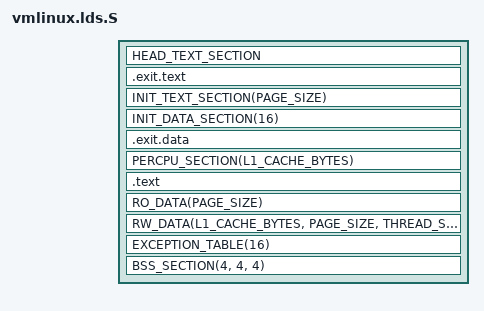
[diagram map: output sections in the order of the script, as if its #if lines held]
FASTVC-BENCH-CORPUS:linux-main-100k-v1-e0bd41dc-8e12-4f1b-978d-a3645ae59da0
// SPDX-License-Identifier: GPL-2.0
// Copyright (C) 2005-2017 Andes Technology Corporation

#include <asm/page.h>
#include <asm/thread_info.h>
#include <asm/cache.h>
#include <asm/memory.h>

#define LOAD_OFFSET	(PAGE_OFFSET - PHYS_OFFSET)
#include <asm-generic/vmlinux.lds.h>

OUTPUT_ARCH(nds32)
ENTRY(_stext_lma)
jiffies = jiffies_64;

#if defined(CONFIG_GCOV_KERNEL)
#define NDS32_EXIT_KEEP(x)	x
#else
#define NDS32_EXIT_KEEP(x)
#endif

SECTIONS
{
	_stext_lma = TEXTADDR - LOAD_OFFSET;
	. = TEXTADDR;
	__init_begin = .;
	HEAD_TEXT_SECTION
	.exit.text : {
		NDS32_EXIT_KEEP(EXIT_TEXT)
	}
	INIT_TEXT_SECTION(PAGE_SIZE)
	INIT_DATA_SECTION(16)
	.exit.data : {
		NDS32_EXIT_KEEP(EXIT_DATA)
	}
	PERCPU_SECTION(L1_CACHE_BYTES)
	__init_end = .;

	. = ALIGN(PAGE_SIZE);
/* bench 2817.0.0 fe54d3631062 */
/* bench 2817.0.1 6be67002a67d */
/* bench 2817.0.2 5b5f895a2352 */
/* bench 2817.0.3 35f7113ea067 */
/* bench 2817.0.4 2ac212b3cbd6 */
	.text : AT(ADDR(.text) - LOAD_OFFSET) {
		_text = .;		/* Text and read-only data	*/
		TEXT_TEXT
		SCHED_TEXT
		CPUIDLE_TEXT
		LOCK_TEXT
		KPROBES_TEXT
		IRQENTRY_TEXT
		SOFTIRQENTRY_TEXT
		*(.fixup)
	}
/* bench 19149.3.0 7939d3eb910d */
/* bench 19149.3.1 44624ffdaaa5 */
/* bench 19149.3.2 9352eb8b4933 */
/* bench 19149.3.3 b10278d16733 */
/* bench 19149.3.4 6559f4f60f54 */
/* bench 19149.3.5 1f57c29ded99 */

	_sdata = .;
	RO_DATA(PAGE_SIZE)
	RW_DATA(L1_CACHE_BYTES, PAGE_SIZE, THREAD_SIZE)
	_edata  =  .;

	EXCEPTION_TABLE(16)
	BSS_SECTION(4, 4, 4)
	_end = .;

	STABS_DEBUG
	DWARF_DEBUG
/* bench 20793.1.0 11bb0a916137 */
/* bench 20793.1.1 1aae189cdc01 */
/* bench 20793.1.2 2a6763c7a2e3 */
/* bench 20793.1.3 860060495117 */
/* bench 20793.1.4 7028ac979ce0 */
/* bench 20793.1.5 2f151a78c477 */
/* bench 20793.1.6 b4056eecc76e */
/* bench 20793.1.7 1fc427f15cb8 */
/* bench 20793.1.8 26297d35eacd */
/* bench 20793.1.9 fe372c07367b */
/* bench 20793.1.10 57c4cdac58a5 */
	DISCARDS
}
